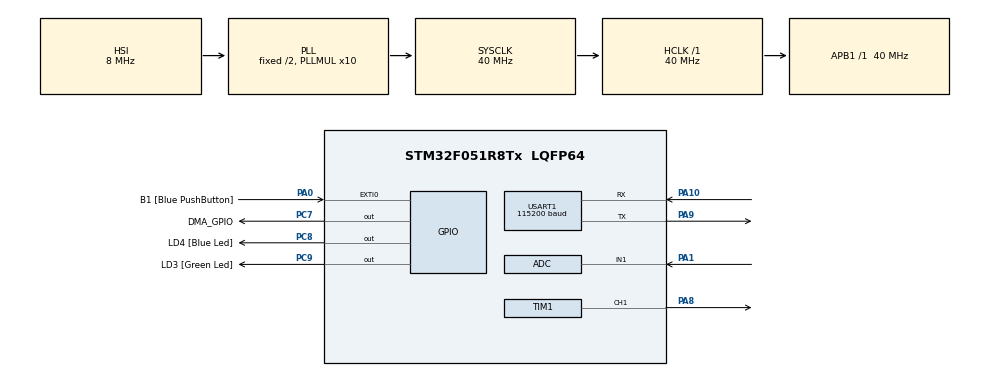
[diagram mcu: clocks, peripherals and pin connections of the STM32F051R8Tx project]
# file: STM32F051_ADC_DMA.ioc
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ADC.ContinuousConvMode=DISABLE
ADC.DMAContinuousRequests=ENABLE
ADC.ExternalTrigConv=ADC_EXTERNALTRIGCONV_T1_TRGO
ADC.ExternalTrigConvEdge=ADC_EXTERNALTRIGCONVEDGE_RISINGFALLING
Dma.ADC.0.Direction=DMA_PERIPH_TO_MEMORY
Dma.ADC.0.Instance=DMA1_Channel1
Dma.ADC.0.MemDataAlignment=DMA_MDATAALIGN_HALFWORD
Dma.ADC.0.MemInc=DMA_MINC_ENABLE
Dma.ADC.0.Mode=DMA_CIRCULAR
Dma.ADC.0.PeriphDataAlignment=DMA_PDATAALIGN_HALFWORD
Dma.ADC.0.PeriphInc=DMA_PINC_DISABLE
Dma.ADC.0.Priority=DMA_PRIORITY_LOW
Dma.Request0=ADC
Mcu.Family=STM32F0
Mcu.Name=STM32F051R8Tx
Mcu.Package=LQFP64
NVIC.DMA1_Channel1_IRQn=true\:0\:0\:false\:false\:true\:false\:true\:true
PA0.GPIO_Label=B1 [Blue PushButton]
PA0.GPIO_ModeDefaultEXTI=GPIO_MODE_EVT_RISING
PA0.Signal=GPXTI0
PA1.Mode=IN1
PA1.Signal=ADC_IN1
PA10.Mode=Asynchronous
PA10.Signal=USART1_RX
PA13.GPIO_Label=SWDIO
PA13.Mode=Serial_Wire
PA13.Signal=SYS_SWDIO
PA14.GPIO_Label=SWCLK
PA14.Mode=Serial_Wire
PA14.Signal=SYS_SWCLK
PA8.Signal=S_TIM1_CH1
PA9.Mode=Asynchronous
PA9.Signal=USART1_TX
PC7.GPIO_Label=DMA_GPIO
PC7.Signal=GPIO_Output
PC8.GPIO_Label=LD4 [Blue Led]
PC8.Signal=GPIO_Output
PC9.GPIO_Label=LD3 [Green Led]
PC9.Signal=GPIO_Output
ProjectManager.HeapSize=0x200
ProjectManager.StackSize=0x400
ProjectManager.TargetToolchain=STM32CubeIDE
RCC.AHBFreq_Value=40000000
RCC.APB1Freq_Value=40000000
RCC.APB1TimFreq_Value=40000000
RCC.HCLKFreq_Value=40000000
RCC.PLLMUL=RCC_PLL_MUL10
RCC.SYSCLKFreq_VALUE=40000000
RCC.SYSCLKSource=RCC_SYSCLKSOURCE_PLLCLK
SH.S_TIM1_CH1.0=TIM1_CH1,Output Compare1 CH1
TIM1.Channel-Output\ Compare1\ CH1=TIM_CHANNEL_1
TIM1.OCMode_1=TIM_OCMODE_TOGGLE
TIM1.Period=1333-1
TIM1.TIM_MasterOutputTrigger=TIM_TRGO_UPDATE
USART1.BaudRate=115200
USART1.VirtualMode-Asynchronous=VM_ASYNC
VP_TIM1_VS_ClockSourceINT.Mode=Internal
board=STM32F0DISCOVERY

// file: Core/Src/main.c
/* USER CODE BEGIN Header */
/**
  ******************************************************************************
  * @file           : main.c
  * @brief          : Main program body
  ******************************************************************************
  * @attention
  *
  * Copyright (c) 2024 STMicroelectronics.
  * All rights reserved.
  *
  * This software is licensed under terms that can be found in the LICENSE file
  * in the root directory of this software component.
  * If no LICENSE file comes with this software, it is provided AS-IS.
  *
  ******************************************************************************
  */
/* USER CODE END Header */
#include "main.h"

/* USER CODE BEGIN Includes */
#include "string.h"
#include "stdio.h"
/* USER CODE END Includes */

/* USER CODE BEGIN PD */
#define ADC_BUF_LEN 10
/* USER CODE END PD */

ADC_HandleTypeDef hadc;
DMA_HandleTypeDef hdma_adc;

TIM_HandleTypeDef htim1;

UART_HandleTypeDef huart1;

/* USER CODE BEGIN PV */
uint16_t adc_buf[ADC_BUF_LEN];
HAL_StatusTypeDef uartTest;
/* USER CODE END PV */

void SystemClock_Config(void);
static void MX_GPIO_Init(void);
static void MX_DMA_Init(void);
static void MX_ADC_Init(void);
static void MX_USART1_UART_Init(void);
static void MX_TIM1_Init(void);

int main(void)
{

  /* MCU Configuration--------------------------------------------------------*/

  /* Reset of all peripherals, Initializes the Flash interface and the Systick. */
  HAL_Init();

  /* Configure the system clock */
  SystemClock_Config();

  /* Initialize all configured peripherals */
  MX_GPIO_Init();
  MX_DMA_Init();
  MX_ADC_Init();
  MX_USART1_UART_Init();
  MX_TIM1_Init();
  /* USER CODE BEGIN 2 */
  HAL_TIM_Base_Start(&htim1);
  HAL_TIM_OC_Start(&htim1, TIM_CHANNEL_1);
  HAL_ADC_Start_DMA(&hadc, (uint32_t*)adc_buf, ADC_BUF_LEN);
  /* USER CODE END 2 */

  /* Infinite loop */
  /* USER CODE BEGIN WHILE */
  while (1)
  {
	  if(uartTest == HAL_OK)
	  {
		  HAL_GPIO_TogglePin(LD3_GPIO_Port, LD3_Pin);
	  }

    /* USER CODE END WHILE */

  }
}

void SystemClock_Config(void)
{
  RCC_OscInitTypeDef RCC_OscInitStruct = {0};
  RCC_ClkInitTypeDef RCC_ClkInitStruct = {0};
  RCC_PeriphCLKInitTypeDef PeriphClkInit = {0};

  /** Initializes the RCC Oscillators according to the specified parameters
  * in the RCC_OscInitTypeDef structure.
  */
  RCC_OscInitStruct.OscillatorType = RCC_OSCILLATORTYPE_HSI|RCC_OSCILLATORTYPE_HSI14;
  RCC_OscInitStruct.HSIState = RCC_HSI_ON;
  RCC_OscInitStruct.HSI14State = RCC_HSI14_ON;
  RCC_OscInitStruct.HSICalibrationValue = RCC_HSICALIBRATION_DEFAULT;
  RCC_OscInitStruct.HSI14CalibrationValue = 16;
  RCC_OscInitStruct.PLL.PLLState = RCC_PLL_ON;
  RCC_OscInitStruct.PLL.PLLSource = RCC_PLLSOURCE_HSI;
  RCC_OscInitStruct.PLL.PLLMUL = RCC_PLL_MUL10;
  RCC_OscInitStruct.PLL.PREDIV = RCC_PREDIV_DIV1;
  if (HAL_RCC_OscConfig(&RCC_OscInitStruct) != HAL_OK)
  {
    Error_Handler();
  }

  /** Initializes the CPU, AHB and APB buses clocks
  */
  RCC_ClkInitStruct.ClockType = RCC_CLOCKTYPE_HCLK|RCC_CLOCKTYPE_SYSCLK
                              |RCC_CLOCKTYPE_PCLK1;
  RCC_ClkInitStruct.SYSCLKSource = RCC_SYSCLKSOURCE_PLLCLK;
  RCC_ClkInitStruct.AHBCLKDivider = RCC_SYSCLK_DIV1;
  RCC_ClkInitStruct.APB1CLKDivider = RCC_HCLK_DIV1;

  if (HAL_RCC_ClockConfig(&RCC_ClkInitStruct, FLASH_LATENCY_1) != HAL_OK)
  {
    Error_Handler();
  }
  PeriphClkInit.PeriphClockSelection = RCC_PERIPHCLK_USART1;
  PeriphClkInit.Usart1ClockSelection = RCC_USART1CLKSOURCE_PCLK1;
  if (HAL_RCCEx_PeriphCLKConfig(&PeriphClkInit) != HAL_OK)
  {
    Error_Handler();
  }
}

static void MX_ADC_Init(void)
{

  ADC_ChannelConfTypeDef sConfig = {0};

  /** Configure the global features of the ADC (Clock, Resolution, Data Alignment and number of conversion)
  */
  hadc.Instance = ADC1;
  hadc.Init.ClockPrescaler = ADC_CLOCK_ASYNC_DIV1;
  hadc.Init.Resolution = ADC_RESOLUTION_12B;
  hadc.Init.DataAlign = ADC_DATAALIGN_RIGHT;
  hadc.Init.ScanConvMode = ADC_SCAN_DIRECTION_FORWARD;
  hadc.Init.EOCSelection = ADC_EOC_SINGLE_CONV;
  hadc.Init.LowPowerAutoWait = DISABLE;
  hadc.Init.LowPowerAutoPowerOff = DISABLE;
  hadc.Init.ContinuousConvMode = DISABLE;
  hadc.Init.DiscontinuousConvMode = DISABLE;
  hadc.Init.ExternalTrigConv = ADC_EXTERNALTRIGCONV_T1_TRGO;
  hadc.Init.ExternalTrigConvEdge = ADC_EXTERNALTRIGCONVEDGE_RISINGFALLING;
  hadc.Init.DMAContinuousRequests = ENABLE;
  hadc.Init.Overrun = ADC_OVR_DATA_PRESERVED;
  if (HAL_ADC_Init(&hadc) != HAL_OK)
  {
    Error_Handler();
  }

  /** Configure for the selected ADC regular channel to be converted.
  */
  sConfig.Channel = ADC_CHANNEL_1;
  sConfig.Rank = ADC_RANK_CHANNEL_NUMBER;
  sConfig.SamplingTime = ADC_SAMPLETIME_1CYCLE_5;
  if (HAL_ADC_ConfigChannel(&hadc, &sConfig) != HAL_OK)
  {
    Error_Handler();
  }

}

static void MX_TIM1_Init(void)
{

  TIM_ClockConfigTypeDef sClockSourceConfig = {0};
  TIM_MasterConfigTypeDef sMasterConfig = {0};
  TIM_OC_InitTypeDef sConfigOC = {0};
  TIM_BreakDeadTimeConfigTypeDef sBreakDeadTimeConfig = {0};

  htim1.Instance = TIM1;
  htim1.Init.Prescaler = 0;
  htim1.Init.CounterMode = TIM_COUNTERMODE_UP;
  htim1.Init.Period = 1333-1;
  htim1.Init.ClockDivision = TIM_CLOCKDIVISION_DIV1;
  htim1.Init.RepetitionCounter = 0;
  htim1.Init.AutoReloadPreload = TIM_AUTORELOAD_PRELOAD_DISABLE;
  if (HAL_TIM_Base_Init(&htim1) != HAL_OK)
  {
    Error_Handler();
  }
  sClockSourceConfig.ClockSource = TIM_CLOCKSOURCE_INTERNAL;
  if (HAL_TIM_ConfigClockSource(&htim1, &sClockSourceConfig) != HAL_OK)
  {
    Error_Handler();
  }
  if (HAL_TIM_OC_Init(&htim1) != HAL_OK)
  {
    Error_Handler();
  }
  sMasterConfig.MasterOutputTrigger = TIM_TRGO_UPDATE;
  sMasterConfig.MasterSlaveMode = TIM_MASTERSLAVEMODE_DISABLE;
  if (HAL_TIMEx_MasterConfigSynchronization(&htim1, &sMasterConfig) != HAL_OK)
  {
    Error_Handler();
  }
  sConfigOC.OCMode = TIM_OCMODE_TOGGLE;
  sConfigOC.Pulse = 0;
  sConfigOC.OCPolarity = TIM_OCPOLARITY_HIGH;
  sConfigOC.OCNPolarity = TIM_OCNPOLARITY_HIGH;
  sConfigOC.OCFastMode = TIM_OCFAST_DISABLE;
  sConfigOC.OCIdleState = TIM_OCIDLESTATE_RESET;
  sConfigOC.OCNIdleState = TIM_OCNIDLESTATE_RESET;
  if (HAL_TIM_OC_ConfigChannel(&htim1, &sConfigOC, TIM_CHANNEL_1) != HAL_OK)
  {
    Error_Handler();
  }
  sBreakDeadTimeConfig.OffStateRunMode = TIM_OSSR_DISABLE;
  sBreakDeadTimeConfig.OffStateIDLEMode = TIM_OSSI_DISABLE;
  sBreakDeadTimeConfig.LockLevel = TIM_LOCKLEVEL_OFF;
  sBreakDeadTimeConfig.DeadTime = 0;
  sBreakDeadTimeConfig.BreakState = TIM_BREAK_DISABLE;
  sBreakDeadTimeConfig.BreakPolarity = TIM_BREAKPOLARITY_HIGH;
  sBreakDeadTimeConfig.AutomaticOutput = TIM_AUTOMATICOUTPUT_DISABLE;
  if (HAL_TIMEx_ConfigBreakDeadTime(&htim1, &sBreakDeadTimeConfig) != HAL_OK)
  {
    Error_Handler();
  }
  HAL_TIM_MspPostInit(&htim1);

}

static void MX_USART1_UART_Init(void)
{

  huart1.Instance = USART1;
  huart1.Init.BaudRate = 115200;
  huart1.Init.WordLength = UART_WORDLENGTH_8B;
  huart1.Init.StopBits = UART_STOPBITS_1;
  huart1.Init.Parity = UART_PARITY_NONE;
  huart1.Init.Mode = UART_MODE_TX_RX;
  huart1.Init.HwFlowCtl = UART_HWCONTROL_NONE;
  huart1.Init.OverSampling = UART_OVERSAMPLING_16;
  huart1.Init.OneBitSampling = UART_ONE_BIT_SAMPLE_DISABLE;
  huart1.AdvancedInit.AdvFeatureInit = UART_ADVFEATURE_NO_INIT;
  if (HAL_UART_Init(&huart1) != HAL_OK)
  {
    Error_Handler();
  }

}

static void MX_DMA_Init(void)
{

  /* DMA controller clock enable */
  __HAL_RCC_DMA1_CLK_ENABLE();

  /* DMA interrupt init */
  /* DMA1_Channel1_IRQn interrupt configuration */
  HAL_NVIC_SetPriority(DMA1_Channel1_IRQn, 0, 0);
  HAL_NVIC_EnableIRQ(DMA1_Channel1_IRQn);

}

static void MX_GPIO_Init(void)
{
  GPIO_InitTypeDef GPIO_InitStruct = {0};

  /* GPIO Ports Clock Enable */
  __HAL_RCC_GPIOA_CLK_ENABLE();
  __HAL_RCC_GPIOC_CLK_ENABLE();

  /*Configure GPIO pin Output Level */
  HAL_GPIO_WritePin(GPIOC, DMA_GPIO_Pin|LD4_Pin|LD3_Pin, GPIO_PIN_RESET);

  /*Configure GPIO pin : B1_Pin */
  GPIO_InitStruct.Pin = B1_Pin;
  GPIO_InitStruct.Mode = GPIO_MODE_EVT_RISING;
  GPIO_InitStruct.Pull = GPIO_NOPULL;
  HAL_GPIO_Init(B1_GPIO_Port, &GPIO_InitStruct);

  /*Configure GPIO pins : DMA_GPIO_Pin LD4_Pin LD3_Pin */
  GPIO_InitStruct.Pin = DMA_GPIO_Pin|LD4_Pin|LD3_Pin;
  GPIO_InitStruct.Mode = GPIO_MODE_OUTPUT_PP;
  GPIO_InitStruct.Pull = GPIO_NOPULL;
  GPIO_InitStruct.Speed = GPIO_SPEED_FREQ_LOW;
  HAL_GPIO_Init(GPIOC, &GPIO_InitStruct);

}

/* USER CODE BEGIN 4 */
void HAL_ADC_ConvHalfCpltCallback(ADC_HandleTypeDef* hadc){
	HAL_UART_Transmit(&huart1, (void*)adc_buf, sizeof(adc_buf) / 2, HAL_MAX_DELAY);

}

void HAL_ADC_ConvCpltCallback(ADC_HandleTypeDef* hadc){
	HAL_UART_Transmit(&huart1, (void*)&adc_buf[ADC_BUF_LEN / 2], sizeof(adc_buf) / 2, HAL_MAX_DELAY);
}

/* USER CODE END 4 */

void Error_Handler(void)
{
  __disable_irq();
  while (1)
  {
  }
}
